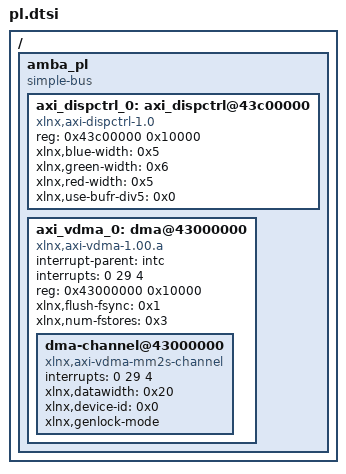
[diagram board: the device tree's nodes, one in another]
/*
 * CAUTION: This file is automatically generated by Xilinx.
 * Version: HSI 2016.2
 * Today is: Wed Aug 17 14:26:41 2016
*/


/ {
	amba_pl: amba_pl {
		#address-cells = <1>;
		#size-cells = <1>;
		compatible = "simple-bus";
		ranges ;
		axi_dispctrl_0: axi_dispctrl@43c00000 {
			compatible = "xlnx,axi-dispctrl-1.0";
			reg = <0x43c00000 0x10000>;
			xlnx,blue-width = <0x5>;
			xlnx,green-width = <0x6>;
			xlnx,red-width = <0x5>;
			xlnx,use-bufr-div5 = <0x0>;
		};
		axi_vdma_0: dma@43000000 {
			#dma-cells = <1>;
			compatible = "xlnx,axi-vdma-1.00.a";
			interrupt-parent = <&intc>;
			interrupts = <0 29 4>;
			reg = <0x43000000 0x10000>;
			xlnx,flush-fsync = <0x1>;
			xlnx,num-fstores = <0x3>;
			dma-channel@43000000 {
				compatible = "xlnx,axi-vdma-mm2s-channel";
				interrupts = <0 29 4>;
				xlnx,datawidth = <0x20>;
				xlnx,device-id = <0x0>;
				xlnx,genlock-mode ;
			};
		};
	};
};
